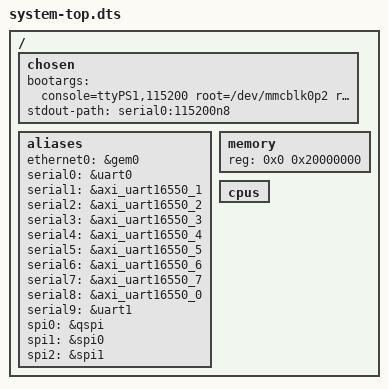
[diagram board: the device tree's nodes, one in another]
/*
 * CAUTION: This file is automatically generated by Xilinx.
 * Version:  
 * Today is: Wed Aug 02 15:55:20 2017
*/


/dts-v1/;
/include/ "zynq-7000.dtsi"
/include/ "pl.dtsi"
/include/ "pcw.dtsi"
/ {
	chosen {
		bootargs = "console=ttyPS1,115200 root=/dev/mmcblk0p2 rw rootwait rootfstype=ext4 noinitrd earlycon";
		stdout-path = "serial0:115200n8";
	};
	aliases {
		ethernet0 = &gem0;
		serial0 = &uart0;
		serial1 = &axi_uart16550_1;
		serial2 = &axi_uart16550_2;
		serial3 = &axi_uart16550_3;
		serial4 = &axi_uart16550_4;
		serial5 = &axi_uart16550_5;
		serial6 = &axi_uart16550_6;
		serial7 = &axi_uart16550_7;
		serial8 = &axi_uart16550_0;
		serial9 = &uart1;
		spi0 = &qspi;
		spi1 = &spi0;
		spi2 = &spi1;
	};
	memory {
		device_type = "memory";
		reg = <0x0 0x20000000>;
	};
	cpus {
	};
};
